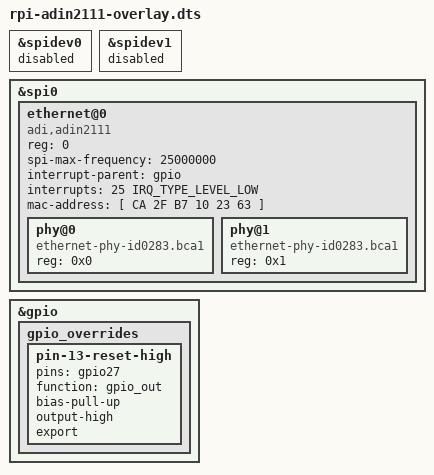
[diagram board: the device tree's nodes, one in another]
// SPDX-License-Identifier: (GPL-2.0+ OR BSD-3-Clause)
/* Overlay for EVAL-ADIN2111EBZ Rev. B
 *
 * Copyright 2022 Analog Devices Inc.
 */

/dts-v1/;
/plugin/;

#include <dt-bindings/interrupt-controller/irq.h>

&spidev0 {
	status = "disabled";
};

&spidev1 {
	status = "disabled";
};

&spi0 {
	#address-cells = <1>;
	#size-cells = <0>;
	status = "okay";

	ethernet@0 {
		compatible = "adi,adin2111";
		reg = <0>;
		spi-max-frequency = <25000000>;

		#address-cells = <1>;
		#size-cells = <0>;

		interrupt-parent = <&gpio>;
		interrupts = <25 IRQ_TYPE_LEVEL_LOW>;
		mac-address = [ CA 2F B7 10 23 63 ];

		phy@0 {
			compatible = "ethernet-phy-id0283.bca1";
			reg = <0x0>;
		};

		phy@1 {
			compatible = "ethernet-phy-id0283.bca1";
			reg = <0x1>;
		};
	};
};

&gpio {
	gpio_overrides: gpio_overrides {
		pin-13-reset-high {
			pins = "gpio27";
			function = "gpio_out";
			bias-pull-up;
			output-high;
			export;
		};
	};
};

